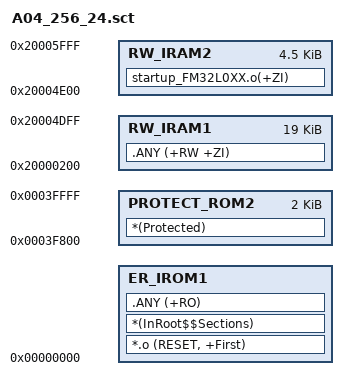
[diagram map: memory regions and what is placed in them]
; *************************************************************
; *** Scatter-Loading Description File generated by uVision ***
; *************************************************************

LR_IROM1 0x00000000 0x0003B800  {    ; load region size_region
  ER_IROM1 0x00000000  {  ; load address = execution address
   *.o (RESET, +First)
   *(InRoot$$Sections)
   .ANY (+RO)
  }
  RW_IRAM1 0x20000200  0x4C00{  ; RW data Power Down
   .ANY (+RW +ZI)
  }
  RW_IRAM2 0x20004E00  0x1200{  ; RW data Power Down
    startup_FM32L0XX.o(+ZI)
  }
}

LR_IROM3 0x0003F800 0x00000800  {
	PROTECT_ROM2 0x0003F800 0x00000800 {
    *(Protected)
  }
}

